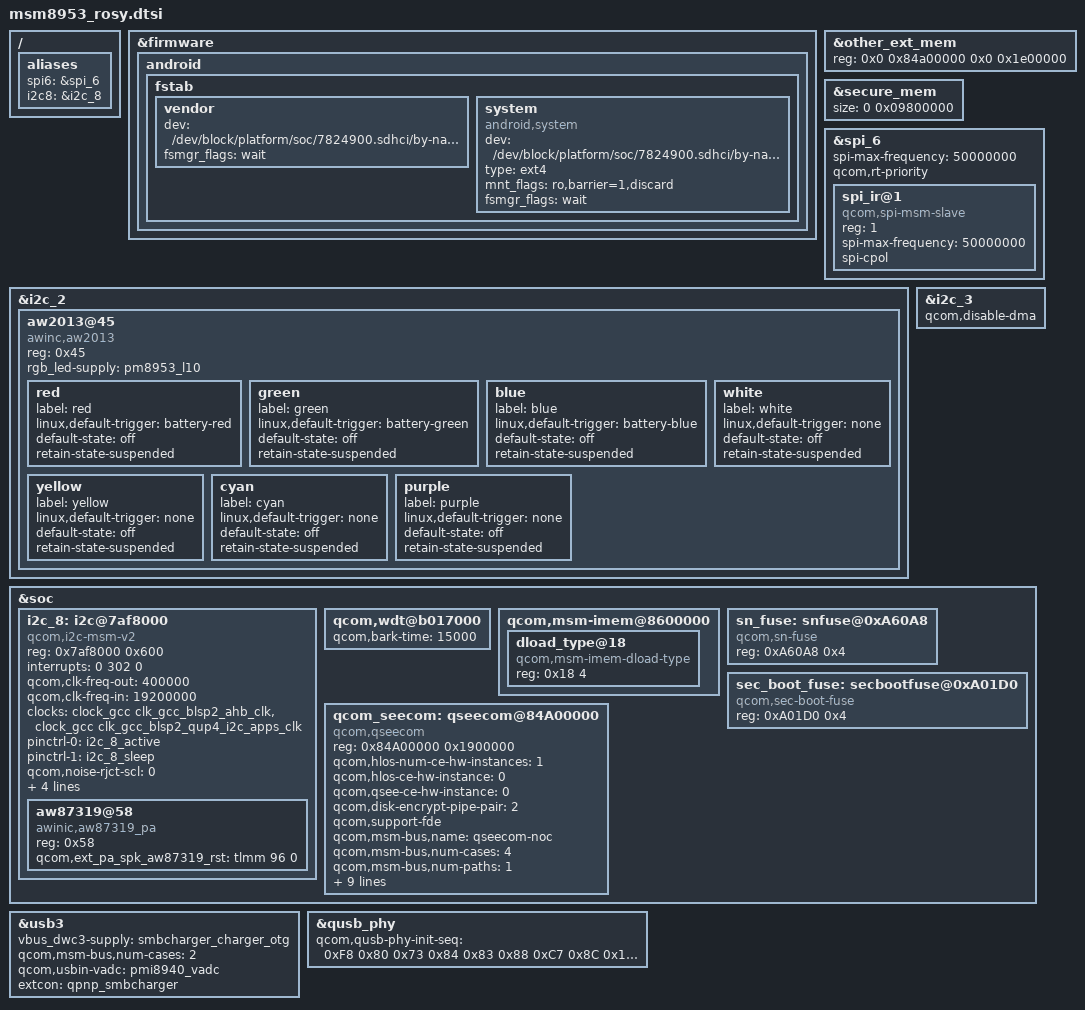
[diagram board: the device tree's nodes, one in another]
&firmware {
	android {
		/delete-node/ vbmeta;
		fstab {
			vendor {
				dev = "/dev/block/platform/soc/7824900.sdhci/by-name/cust";
				fsmgr_flags = "wait";
			};

			system {
				compatible = "android,system";
				dev = "/dev/block/platform/soc/7824900.sdhci/by-name/system";
				type = "ext4";
				mnt_flags = "ro,barrier=1,discard";
				fsmgr_flags = "wait";
				status = "ok";
			};
		};
	};
};

&other_ext_mem { /* 0x1e00000 = 30 MiB */
	reg = <0x0 0x84a00000 0x0 0x1e00000>;
};

&secure_mem {
	size = <0 0x09800000>;
};

/ {
	aliases {
		spi6 = &spi_6;
		i2c8 = &i2c_8;
	};
};

&spi_6 {
	status = "ok";
	spi-max-frequency = <50000000>;
	qcom,rt-priority;

	spi_ir@1 {
		compatible = "qcom,spi-msm-slave"; /* 5637065436e333da0fbbc3e7f23c7a941b8763e8 */
		reg = <1>;
		spi-max-frequency = <50000000>;
		spi-cpol;
		status = "ok";
	};
};

&i2c_2 {
	/delete-node/ adv7533@39;

	aw2013@45 { /*blink */
		compatible = "awinc,aw2013";
		reg = <0x45>;
		rgb_led-supply = <&pm8953_l10>;

		red {
			label = "red";
			linux,default-trigger = "battery-red";
			default-state = "off";
			retain-state-suspended;
		};

		green {
			label = "green";
			linux,default-trigger = "battery-green";
			default-state = "off";
			retain-state-suspended;
		};

		blue {
			label = "blue";
			linux,default-trigger = "battery-blue";
			default-state = "off";
			retain-state-suspended;
		};

		white {
			label = "white";
			linux,default-trigger = "none";
			default-state = "off";
			retain-state-suspended;
		};

		yellow {
			label = "yellow";
			linux,default-trigger = "none";
			default-state = "off";
			retain-state-suspended;
		};

		cyan {
			label = "cyan";
			linux,default-trigger = "none";
			default-state = "off";
			retain-state-suspended;
		};

		purple {
			label = "purple";
			linux,default-trigger = "none";
			default-state = "off";
			retain-state-suspended;
		};
	};
};

&i2c_3 {
	status = "okay";
	qcom,disable-dma;
};

&soc {
	i2c_8: i2c@7af8000 { /* BLSP2 QUP3 */
		compatible = "qcom,i2c-msm-v2";
		#address-cells = <1>;
		#size-cells = <0>;
		reg-names = "qup_phys_addr";
		reg = <0x7af8000 0x600>;
		interrupt-names = "qup_irq";
		interrupts = <0 302 0>;
		qcom,clk-freq-out = <400000>;
		qcom,clk-freq-in  = <19200000>;
		clock-names = "iface_clk", "core_clk";
		clocks = <&clock_gcc clk_gcc_blsp2_ahb_clk>,
			 <&clock_gcc clk_gcc_blsp2_qup4_i2c_apps_clk>;
		pinctrl-names = "i2c_active", "i2c_sleep";
		pinctrl-0 = <&i2c_8_active>;
		pinctrl-1 = <&i2c_8_sleep>;
		qcom,noise-rjct-scl = <0>;
		qcom,noise-rjct-sda = <0>;
		qcom,master-id = <84>;
		dmas = <&dma_blsp2 10 64 0x20000020 0x20>,
			<&dma_blsp2 11 32 0x20000020 0x20>;
		dma-names = "tx", "rx";

		aw87319@58 {
			compatible = "awinic,aw87319_pa";
			reg = <0x58>;
			qcom,ext_pa_spk_aw87319_rst = <&tlmm 96 0>;
		};
	};

	qcom,wdt@b017000 {
		qcom,bark-time = <15000>;
	};

	qcom,msm-imem@8600000 {
		/delete-node/ dload_type@1c;

		dload_type@18 {
			compatible = "qcom,msm-imem-dload-type";
			reg = <0x18 4>;
		};
	};

	sn_fuse: snfuse@0xA60A8 {
		compatible = "qcom,sn-fuse";
		reg = <0xA60A8 0x4>;
		reg-names = "sn-base";
	};

	sec_boot_fuse: secbootfuse@0xA01D0 {
		compatible = "qcom,sec-boot-fuse";
		reg = <0xA01D0 0x4>;
		reg-names = "sec-boot-base";
	};

	/delete-node/ qseecom@85b00000;

	qcom_seecom: qseecom@84A00000 {
		compatible = "qcom,qseecom";
		reg = <0x84A00000 0x1900000>;
		reg-names = "secapp-region";
		qcom,hlos-num-ce-hw-instances = <1>;
		qcom,hlos-ce-hw-instance = <0>;
		qcom,qsee-ce-hw-instance = <0>;
		qcom,disk-encrypt-pipe-pair = <2>;
		qcom,support-fde;
		qcom,msm-bus,name = "qseecom-noc";
		qcom,msm-bus,num-cases = <4>;
		qcom,msm-bus,num-paths = <1>;
		qcom,support-bus-scaling;
		qcom,msm-bus,vectors-KBps =
			<55 512 0 0>,
			<55 512 0 0>,
			<55 512 120000 1200000>,
			<55 512 393600 3936000>;
		clocks = <&clock_gcc clk_crypto_clk_src>,
			 <&clock_gcc clk_gcc_crypto_clk>,
			 <&clock_gcc clk_gcc_crypto_ahb_clk>,
			 <&clock_gcc clk_gcc_crypto_axi_clk>;
		clock-names = "core_clk_src", "core_clk",
			      "iface_clk", "bus_clk";
		qcom,ce-opp-freq = <100000000>;
	};
};

&usb3 {
	vbus_dwc3-supply = <&smbcharger_charger_otg>;
	qcom,msm-bus,num-cases = <2>;
	qcom,usbin-vadc = <&pmi8940_vadc>;
	extcon = <&qpnp_smbcharger>;
};

&qusb_phy {
	qcom,qusb-phy-init-seq = <0xF8 0x80
				  0x73 0x84
				  0x83 0x88
				  0xC7 0x8C
				  0x14 0x9C
				  0x30 0x08
				  0x79 0x0C
				  0x21 0x10
				  0x00 0x90
				  0x9F 0x1C
				  0x00 0x18>;
};
